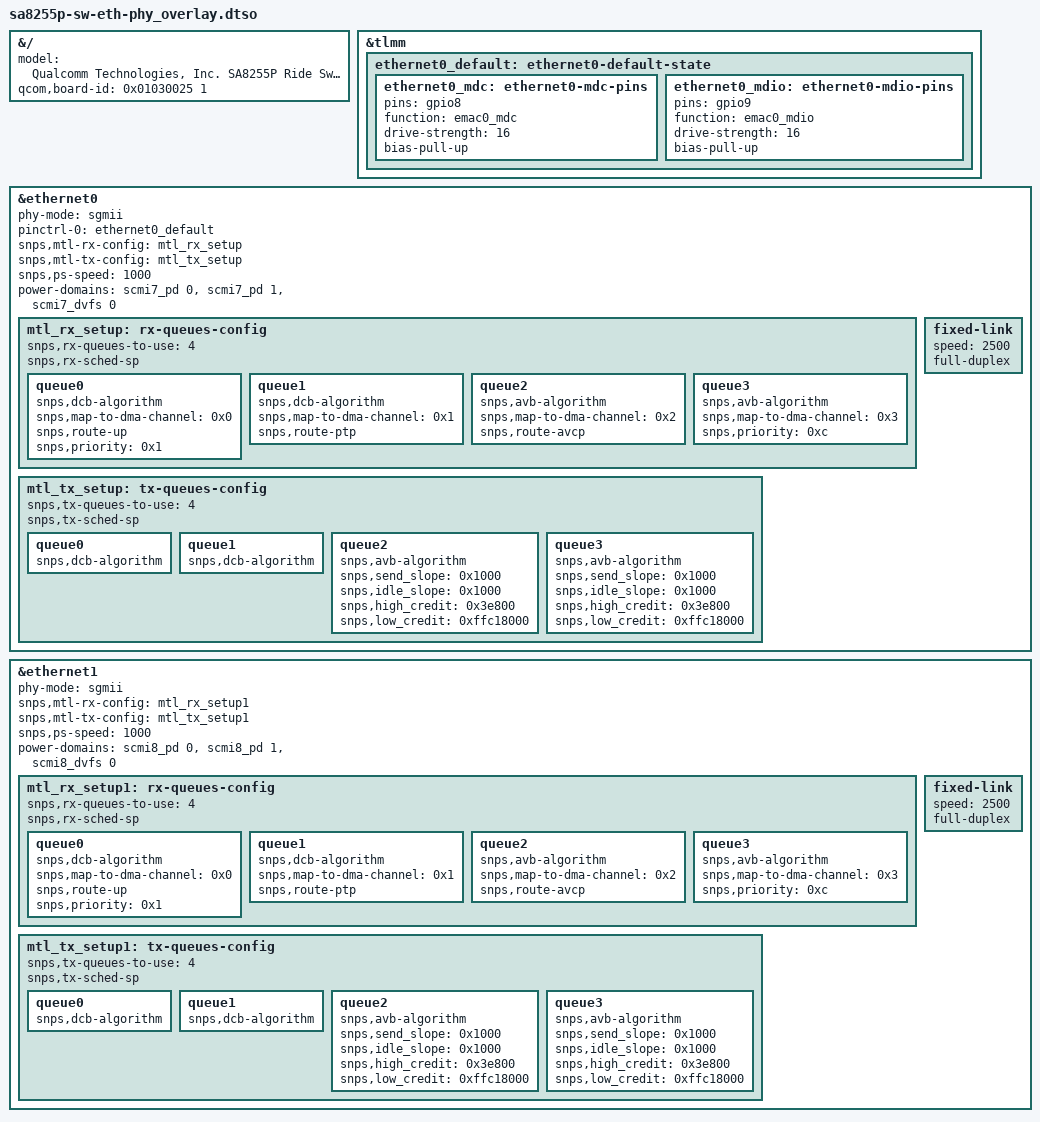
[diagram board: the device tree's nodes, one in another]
// SPDX-License-Identifier: BSD-3-Clause
/*
 * Copyright (c) 2025 Qualcomm Innovation Center, Inc. All rights reserved.
 */

#include "sa8255p_overlay.dtso"

&{/} {
	model = "Qualcomm Technologies, Inc. SA8255P Ride Switch Ethernet PHY";
	qcom,board-id = <0x01030025 1>;
};

&tlmm {
	ethernet0_default: ethernet0-default-state {
		ethernet0_mdc: ethernet0-mdc-pins {
			pins = "gpio8";
			function = "emac0_mdc";
			drive-strength = <16>;
			bias-pull-up;
		};

		ethernet0_mdio: ethernet0-mdio-pins {
			pins = "gpio9";
			function = "emac0_mdio";
			drive-strength = <16>;
			bias-pull-up;
		};
	};
};

&ethernet0 {
	phy-mode = "sgmii";

	pinctrl-0 = <&ethernet0_default>;
	pinctrl-names = "default";

	snps,mtl-rx-config = <&mtl_rx_setup>;
	snps,mtl-tx-config = <&mtl_tx_setup>;
	snps,ps-speed = <1000>;

	power-domains = <&scmi7_pd 0>, <&scmi7_pd 1>,<&scmi7_dvfs 0>;
	power-domain-names = "power_core", "power_mdio","perf_serdes";

	status = "okay";

	mtl_rx_setup: rx-queues-config {
		snps,rx-queues-to-use = <4>;
		snps,rx-sched-sp;

		queue0 {
			snps,dcb-algorithm;
			snps,map-to-dma-channel = <0x0>;
			snps,route-up;
			snps,priority = <0x1>;
		};

		queue1 {
			snps,dcb-algorithm;
			snps,map-to-dma-channel = <0x1>;
			snps,route-ptp;
		};

		queue2 {
			snps,avb-algorithm;
			snps,map-to-dma-channel = <0x2>;
			snps,route-avcp;
		};

		queue3 {
			snps,avb-algorithm;
			snps,map-to-dma-channel = <0x3>;
			snps,priority = <0xc>;
		};
	};

	mtl_tx_setup: tx-queues-config {
		snps,tx-queues-to-use = <4>;
		snps,tx-sched-sp;

		queue0 {
			snps,dcb-algorithm;
		};

		queue1 {
			snps,dcb-algorithm;
		};

		queue2 {
			snps,avb-algorithm;
			snps,send_slope = <0x1000>;
			snps,idle_slope = <0x1000>;
			snps,high_credit = <0x3e800>;
			snps,low_credit = <0xffc18000>;
		};

		queue3 {
			snps,avb-algorithm;
			snps,send_slope = <0x1000>;
			snps,idle_slope = <0x1000>;
			snps,high_credit = <0x3e800>;
			snps,low_credit = <0xffc18000>;
		};
	};

	fixed-link {
		status = "okay";
		speed = <2500>;
		full-duplex;
	};
};

&ethernet1 {
	phy-mode = "sgmii";

	snps,mtl-rx-config = <&mtl_rx_setup1>;
	snps,mtl-tx-config = <&mtl_tx_setup1>;
	snps,ps-speed = <1000>;

	power-domains = <&scmi8_pd 0>, <&scmi8_pd 1>,<&scmi8_dvfs 0>;
	power-domain-names = "power_core", "power_mdio","perf_serdes";

	status = "okay";

	mtl_rx_setup1: rx-queues-config {
		snps,rx-queues-to-use = <4>;
		snps,rx-sched-sp;

		queue0 {
			snps,dcb-algorithm;
			snps,map-to-dma-channel = <0x0>;
			snps,route-up;
			snps,priority = <0x1>;
		};

		queue1 {
			snps,dcb-algorithm;
			snps,map-to-dma-channel = <0x1>;
			snps,route-ptp;
		};

		queue2 {
			snps,avb-algorithm;
			snps,map-to-dma-channel = <0x2>;
			snps,route-avcp;
		};

		queue3 {
			snps,avb-algorithm;
			snps,map-to-dma-channel = <0x3>;
			snps,priority = <0xc>;
		};
	};

	mtl_tx_setup1: tx-queues-config {
		snps,tx-queues-to-use = <4>;
		snps,tx-sched-sp;

		queue0 {
			snps,dcb-algorithm;
		};

		queue1 {
			snps,dcb-algorithm;
		};

		queue2 {
			snps,avb-algorithm;
			snps,send_slope = <0x1000>;
			snps,idle_slope = <0x1000>;
			snps,high_credit = <0x3e800>;
			snps,low_credit = <0xffc18000>;
		};

		queue3 {
			snps,avb-algorithm;
			snps,send_slope = <0x1000>;
			snps,idle_slope = <0x1000>;
			snps,high_credit = <0x3e800>;
			snps,low_credit = <0xffc18000>;
		};
	};

        fixed-link {
                status = "okay";
                speed = <2500>;
                full-duplex;
        };

};
